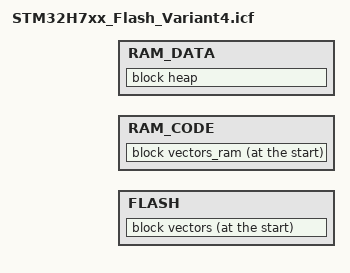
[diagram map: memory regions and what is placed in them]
/*********************************************************************
*                    SEGGER Microcontroller GmbH                     *
*                        The Embedded Experts                        *
**********************************************************************
*                                                                    *
*            (c) 2014 - 2020 SEGGER Microcontroller GmbH             *
*                                                                    *
*       www.segger.com     Support: support@segger.com               *
*                                                                    *
**********************************************************************
*                                                                    *
* All rights reserved.                                               *
*                                                                    *
* Redistribution and use in source and binary forms, with or         *
* without modification, are permitted provided that the following    *
* condition is met:                                                  *
*                                                                    *
* - Redistributions of source code must retain the above copyright   *
*   notice, this condition and the following disclaimer.             *
*                                                                    *
* THIS SOFTWARE IS PROVIDED BY THE COPYRIGHT HOLDERS AND             *
* CONTRIBUTORS "AS IS" AND ANY EXPRESS OR IMPLIED WARRANTIES,        *
* INCLUDING, BUT NOT LIMITED TO, THE IMPLIED WARRANTIES OF           *
* MERCHANTABILITY AND FITNESS FOR A PARTICULAR PURPOSE ARE           *
* DISCLAIMED. IN NO EVENT SHALL SEGGER Microcontroller BE LIABLE FOR *
* ANY DIRECT, INDIRECT, INCIDENTAL, SPECIAL, EXEMPLARY, OR           *
* CONSEQUENTIAL DAMAGES (INCLUDING, BUT NOT LIMITED TO, PROCUREMENT  *
* OF SUBSTITUTE GOODS OR SERVICES; LOSS OF USE, DATA, OR PROFITS;    *
* OR BUSINESS INTERRUPTION) HOWEVER CAUSED AND ON ANY THEORY OF      *
* LIABILITY, WHETHER IN CONTRACT, STRICT LIABILITY, OR TORT          *
* (INCLUDING NEGLIGENCE OR OTHERWISE) ARISING IN ANY WAY OUT OF THE  *
* USE OF THIS SOFTWARE, EVEN IF ADVISED OF THE POSSIBILITY OF SUCH   *
* DAMAGE.                                                            *
*                                                                    *
**********************************************************************
-------------------------- END-OF-HEADER -----------------------------

File    : STM32H7xx_Flash_Variant4.icf
Purpose : STM32H7xx linker script for application placement in Flash,
          for use with the SEGGER Linker.
Maps    : STM32H745BGTx_CM7, STM32H745BITx_CM7, STM32H745IGKx_CM7, STM32H745IGTx_CM7, 
          STM32H745IIKx_CM7, STM32H745IITx_CM7, STM32H745XGHx_CM7, STM32H745XIHx_CM7, 
          STM32H745ZGTx_CM7, STM32H745ZITx_CM7, STM32H747AGIx_CM7, STM32H747AIIx_CM7, 
          STM32H747BGTx_CM7, STM32H747BITx_CM7, STM32H747IGTx_CM7, STM32H747IITx_CM7, 
          STM32H747XGHx_CM7, STM32H747XIHx_CM7, STM32H747ZIYx_CM7, STM32H750IBKx, 
          STM32H750IBTx, STM32H750VBTx, STM32H750XBHx, STM32H753BITx, 
          STM32H753IIKx, STM32H753IITx, STM32H753VIHx, STM32H753VITx, 
          STM32H753XIHx, STM32H753ZITx, STM32H755BITx_CM7, STM32H755IIKx_CM7, 
          STM32H755IITx_CM7, STM32H755XIHx_CM7, STM32H755ZITx_CM7, STM32H757AIIx_CM7, 
          STM32H757BITx_CM7, STM32H757IITx_CM7, STM32H757XIHx_CM7, STM32H757ZIYx_CM7
Literature:
  [1]  SEGGER Linker User Guide (https://www.segger.com/doc/UM20005_Linker.html)
  [2]  SEGGER Linker Sction Placement (https://wiki.segger.com/SEGGER_Linker_Section_Placement)
*/

define memory with size = 4G;

//
// Combined regions per memory type
//
define region FLASH = FLASH1;
define region RAM_CODE   = ITCM_RAM1;
define region RAM_DATA   = DTCM_RAM1 + AXI_RAM1;
//
// Block definitions
//
define block vectors                        { section .vectors };                                   // Vector table section
define block vectors_ram                    { section .vectors_ram };                               // Vector table section
define block ctors                          { section .ctors,     section .ctors.*, block with         alphabetical order { init_array } };
define block dtors                          { section .dtors,     section .dtors.*, block with reverse alphabetical order { fini_array } };
define block exidx                          { section .ARM.exidx, section .ARM.exidx.* };
define block tbss                           { section .tbss,      section .tbss.*  };
define block tdata                          { section .tdata,     section .tdata.* };
define block tls                            { block tbss, block tdata };
define block tdata_load                     { copy of block tdata };
define block heap  with size = __HEAPSIZE__,  alignment = 8, /* fill =0x00, */ readwrite access { };
define block stack with size = __STACKSIZE__, alignment = 8, /* fill =0xCD, */ readwrite access { };


//
// Explicit initialization settings for sections
// Packing options for initialize by copy: packing=auto/lzss/zpak/packbits
//
do not initialize                           { section .non_init, section .non_init.*, section .*.non_init, section .*.non_init.* };
do not initialize                           { section .no_init, section .no_init.*, section .*.no_init, section .*.no_init.* };   // Legacy sections, kept for backwards compatibility
do not initialize                           { section .noinit, section .noinit.*, section .*.noinit, section .*.noinit.* };       // Legacy sections, used by some SDKs/HALs
do not initialize                           { block vectors_ram };
initialize by copy with packing=auto        { section .data, section .data.*, section .*.data, section .*.data.* };               // Static data sections
initialize by copy with packing=auto        { section .fast, section .fast.* };                                                   // "RAM Code" sections
initialize by symbol __SEGGER_init_heap     { block heap  };                                        // Init the heap if there is one
initialize by symbol __SEGGER_init_ctors    { block ctors };                                        // Call constructors for global objects which need to be constructed before reaching main (if any). Make sure this is done after setting up heap.

//
// Explicit placement in FLASHn
//
place in FLASH1                             { section .FLASH1, section .FLASH1.* };
//
// FLASH Placement
//
place at start of FLASH                     { block vectors };                                      // Vector table section
place in FLASH with minimum size order      { block tdata_load,                                     // Thread-local-storage load image
                                              block exidx,                                          // ARM exception unwinding block
                                              block ctors,                                          // Constructors block
                                              block dtors,                                          // Destructors block
                                              readonly,                                             // Catch-all for readonly data (e.g. .rodata, .srodata)
                                              readexec                                              // Catch-all for (readonly) executable code (e.g. .text)
                                            };



//
// Explicit placement in RAMn
//
place in ITCM_RAM1                          { section .ITCM_RAM1, section .ITCM_RAM1.* };
place in DTCM_RAM1                          { section .DTCM_RAM1, section .DTCM_RAM1.* };
place in AXI_RAM1                           { section .AXI_RAM1, section .AXI_RAM1.* };
place in RAM1                               { section .RAM1, section .RAM1.* };
place in RAM2                               { section .RAM2, section .RAM2.* };
place in RAM3                               { section .RAM3, section .RAM3.* };
place in RAM4                               { section .RAM4, section .RAM4.* };
place in Backup_RAM1                        { section .Backup_RAM1, section .Backup_RAM1.* };
//
// RAM Placement
//
                    
place at end of DTCM_RAM1                   { block stack };                                        // Stack reserved block at the end
place in RAM_DATA with auto order           { block tls,                                            // Thread-local-storage block
                                              readwrite,                                            // Catch-all for initialized/uninitialized data sections (e.g. .data, .noinit)
                                              zeroinit                                              // Catch-all for zero-initialized data sections (e.g. .bss)
                                            };

place in RAM_DATA                           { block heap };                                         // Heap reserved block



define block code_tx { section .text.tx_*, section .text._tx_*, section .text._txe_*, section .text._txr_* };
define block code_fx { section .text.fx_*, section .text._fx_*, section .text._fxe_*, section .text._fxr_* };
define block code_isr { section .init.*_IRQHandler, section .text.*_IRQHandler, section .text.*Callback };
define block code_libc { section .text.libc.* };

initialize by copy with packing=auto   { section .RAM1.DATA^.*
                                                    , section .RAM2.DATA^.*
                                                    , section .RAM3.DATA^.*
                                                    , section .RAM4.DATA^.*
                                                    , section .Backup_RAM1.DATA^.*
                                                    , section .AXI_RAM1.DATA^.*
                                                    };
initialize by copy with packing=auto        { block code_tx
                                            , block code_isr
                                            , block code_fx
                                            , block code_libc 
                                            };   


place at start of RAM_CODE                        { block vectors_ram };
place in RAM_CODE with auto order                 { section .fast
                                                  , section .fast.*
                                                  , block code_libc
                                                  , block code_isr
                                                  , block code_tx
                                                  , block code_fx
                                                  };   // "ramfunc" section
